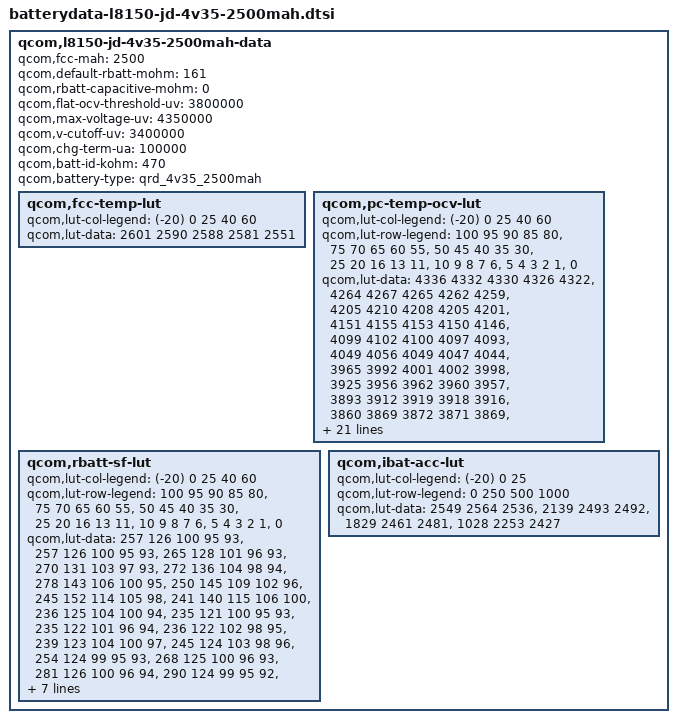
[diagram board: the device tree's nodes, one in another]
qcom,l8150-jd-4v35-2500mah-data {
	qcom,fcc-mah = <2500>;
	qcom,default-rbatt-mohm = <161>;
	qcom,rbatt-capacitive-mohm = <0>;
	qcom,flat-ocv-threshold-uv = <3800000>;
	qcom,max-voltage-uv = <4350000>;
	qcom,v-cutoff-uv = <3400000>;
	qcom,chg-term-ua = <100000>;
	qcom,batt-id-kohm = <470>;
	qcom,battery-type = "qrd_4v35_2500mah";

	qcom,fcc-temp-lut {
		qcom,lut-col-legend = <(-20) 0 25 40 60>;
		qcom,lut-data = <2601 2590 2588 2581 2551>;
    };
	qcom,pc-temp-ocv-lut {
		qcom,lut-col-legend = <(-20) 0 25 40 60>;
		qcom,lut-row-legend = <100 95 90 85 80>,
				<75 70 65 60 55>,
				<50 45 40 35 30>,
				<25 20 16 13 11>,
				<10 9 8 7 6>,
				<5 4 3 2 1>,
				<0>;
		qcom,lut-data = <4336 4332 4330 4326 4322>,
				<4264 4267 4265 4262 4259>,
				<4205 4210 4208 4205 4201>,
				<4151 4155 4153 4150 4146>,
				<4099 4102 4100 4097 4093>,
				<4049 4056 4049 4047 4044>,
				<3965 3992 4001 4002 3998>,
				<3925 3956 3962 3960 3957>,
				<3893 3912 3919 3918 3916>,
				<3860 3869 3872 3871 3869>,
				<3832 3839 3839 3838 3838>,
				<3810 3816 3817 3815 3814>,
				<3791 3798 3798 3797 3795>,
				<3778 3783 3783 3782 3779>,
				<3768 3771 3767 3762 3756>,
				<3756 3759 3747 3738 3725>,
				<3739 3742 3729 3719 3703>,
				<3721 3722 3709 3698 3684>,
				<3707 3701 3688 3678 3664>,
				<3700 3693 3681 3673 3660>,
				<3696 3691 3680 3672 3659>,
				<3693 3690 3679 3670 3657>,
				<3688 3688 3677 3669 3656>,
				<3681 3685 3674 3666 3652>,
				<3668 3679 3666 3657 3638>,
				<3635 3657 3641 3629 3604>,
				<3583 3614 3597 3585 3557>,
				<3511 3555 3537 3520 3497>,
				<3408 3475 3457 3439 3418>,
				<3239 3356 3336 3311 3299>,
				<3000 3000 3000 3000 3044>;
    };
	qcom,rbatt-sf-lut {
		qcom,lut-col-legend = <(-20) 0 25 40 60>;
		qcom,lut-row-legend = <100 95 90 85 80>,
				<75 70 65 60 55>,
				<50 45 40 35 30>,
				<25 20 16 13 11>,
				<10 9 8 7 6>,
				<5 4 3 2 1>,
				<0>;
		qcom,lut-data = <257 126 100 95 93>,
				<257 126 100 95 93>,
				<265 128 101 96 93>,
				<270 131 103 97 93>,
				<272 136 104 98 94>,
				<278 143 106 100 95>,
				<250 145 109 102 96>,
				<245 152 114 105 98>,
				<241 140 115 106 100>,
				<236 125 104 100 94>,
				<235 121 100 95 93>,
				<235 122 101 96 94>,
				<236 122 102 98 95>,
				<239 123 104 100 97>,
				<245 124 103 98 96>,
				<254 124 99 95 93>,
				<268 125 100 96 93>,
				<281 126 100 96 94>,
				<290 124 99 95 92>,
				<311 125 99 95 93>,
				<326 126 101 97 94>,
				<345 129 103 98 96>,
				<368 131 104 101 100>,
				<396 135 106 103 102>,
				<427 139 108 104 99>,
				<450 139 105 98 96>,
				<508 139 104 100 96>,
				<604 145 108 103 100>,
				<764 158 116 111 104>,
				<1784 194 142 149 118>,
				<193225 126232 155340 133021 547>;
    };

	qcom,ibat-acc-lut {
		qcom,lut-col-legend = <(-20) 0 25>;
		qcom,lut-row-legend = <0 250 500 1000>;
		qcom,lut-data = <2549 2564 2536>,
				<2139 2493 2492>,
				<1829 2461 2481>,
				<1028 2253 2427>;
	};

};
